# NUC200AE_v1 register map
File version: 1.0
Registers are 32-bit, read-write, reset 0x0 unless marked. A register's access mark holds for its fields unless they carry their own. Offsets are from the block's base; [hi:lo] are bit positions; {n}, {i} and the like mark numbered series.

## PDMA_GCR — PDMA Register Map
Base 0x50008F00
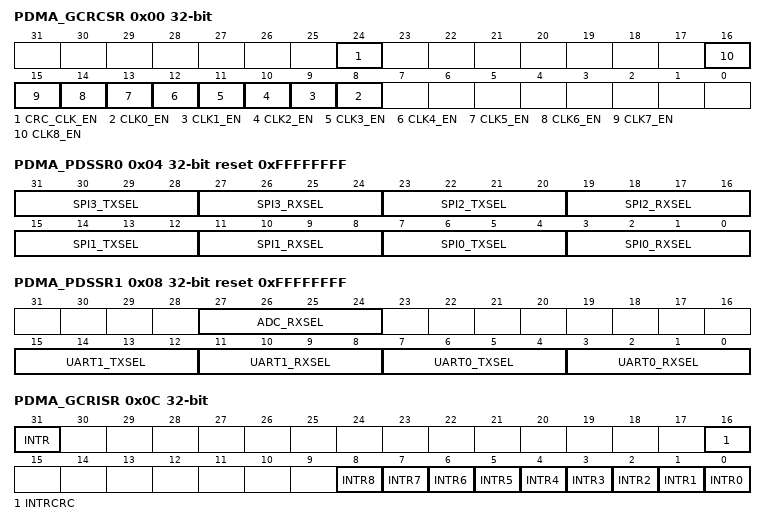
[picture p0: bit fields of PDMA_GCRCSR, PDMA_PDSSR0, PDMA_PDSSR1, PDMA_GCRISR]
0x00 PDMA_GCRCSR — PDMA Global Control Register
  [all] fields
    0=Disabled; 1=Enabled
  [24] CRC_CLK_EN — CRC Controller Clock Enable Bit
  [n+8] CLK{n}_EN (n=0..8) — PDMA Controller Channel {n} Clock Enable Bit
0x04 PDMA_PDSSR0 reset 0xFFFFFFFF — PDMA Service Selection Control Register 0
  [8n+7:8n+4] SPI{n}_TXSEL (n=0..3) — PDMA SPI{n} TX Selection. This field defines which PDMA channel is connected to the on-chip peripheral SPI{n} TX. Software can configure the TX channel setting by this field. The channel configuration is the same as SPI0_RXSEL (PDMA_PDSSR0[3:0]) field. Please refer to the explanation of SPI0_RXSEL (PDMA_PDSSR0[3:0]).
  [27:24] SPI3_RXSEL — PDMA SPI3 RX Selection. This field defines which PDMA channel is connected to the on-chip peripheral SPI3 RX. Software can configure the RX channel setting by this field. The channel configuration is the same as SPI0_RXSEL (PDMA_PDSSR0[3:0]) field. Please refer to the explanation of SPI0_RXSEL (PDMA_PDSSR0[3:0]).
  [19:16] SPI2_RXSEL — PDMA SPI2 RX Selection. This field defines which PDMA channel is connected to the on-chip peripheral SPI2 RX. Software can configure the RX channel setting by this field. The channel configuration is the same as SPI0_RXSEL (PDMA_PDSSR0[3:0]) field. Please refer to the explanation of SPI0_RXSEL (PDMA_PDSSR0[3:0]).
  [11:8] SPI1_RXSEL — PDMA SPI1 RX Selection. This field defines which PDMA channel is connected to the on-chip peripheral SPI1 RX. Software can configure the RX channel setting by this field. The channel configuration is the same as SPI0_RXSEL (PDMA_PDSSR0[3:0]) field. Please refer to the explanation of SPI0_RXSEL (PDMA_PDSSR0[3:0]).
  [3:0] SPI0_RXSEL — PDMA SPI0 RX Selection. 0000: CH0. 0001: CH1. 0010: CH2. 0011: CH3. 0100: CH4. 0101: CH5. 0110: CH6. 0111: CH7. 1000: CH8. Others : Reserved
0x08 PDMA_PDSSR1 reset 0xFFFFFFFF — PDMA Service Selection Control Register 1
  [27:24] ADC_RXSEL — PDMA ADC RX Selection. This field defines which PDMA channel is connected to the on-chip peripheral ADC RX. Software can configure the RX channel setting by this field. The channel configuration is the same as UART0_RXSEL (PDMA_PDSSR1[3:0]) field. Please refer to the explanation of UART0_RXSEL (PDMA_PDSSR1[3:0]).
  [15:12] UART1_TXSEL — PDMA UART1 TX Selection. This field defines which PDMA channel is connected to the on-chip peripheral UART1 TX. Software can configure the TX channel setting by this field. The channel configuration is the same as UART0_RXSEL (PDMA_PDSSR1[3:0]) field. Please refer to the explanation of UART0_RXSEL (PDMA_PDSSR1[3:0]).
  [11:8] UART1_RXSEL — PDMA UART1 RX Selection. This field defines which PDMA channel is connected to the on-chip peripheral UART1 RX. Software can configure the RX channel setting by this field. The channel configuration is the same as UART0_RXSEL (PDMA_PDSSR1[3:0]) field. Please refer to the explanation of UART0_RXSEL (PDMA_PDSSR1[3:0]).
  [7:4] UART0_TXSEL — PDMA UART0 TX Selection. This field defines which PDMA channel is connected to the on-chip peripheral UART0 TX. Software can configure the TX channel setting by this field. The channel configuration is the same as UART0_RXSEL (PDMA_PDSSR1[3:0]) field. Please refer to the explanation of UART0_RXSEL (PDMA_PDSSR1[3:0]).
  [3:0] UART0_RXSEL — PDMA UART0 RX Selection. 0000: CH0. 0001: CH1. 0010: CH2. 0011: CH3. 0100: CH4. 0101: CH5. 0110: CH6. 0111: CH7. 1000: CH8. Others : Reserved
0x0C PDMA_GCRISR ro — PDMA Global Interrupt Status Register
  [31] INTR — Interrupt Status. This bit is the interrupt status of PDMA controller. Note: This bit is read only.
  [16] INTRCRC — Interrupt Status Of CRC Controller. This bit is the interrupt status of CRC controller. Note: This bit is read only
  [n] INTR{n} (n=0..8) — Interrupt Status Of Channel {n}. This bit is the interrupt status of PDMA channel{n}. Note: This bit is read only.
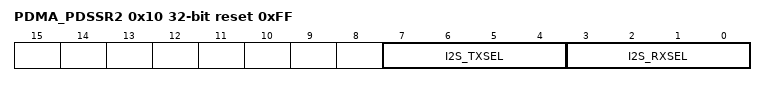
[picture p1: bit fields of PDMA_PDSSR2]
0x10 PDMA_PDSSR2 reset 0xFF — PDMA Service Selection Control Register 2
  [7:4] I2S_TXSEL — PDMA I2S TX Selection. This field defines which PDMA channel is connected to the on-chip peripheral I2S TX. Software can configure the TX channel setting by this field. The channel configuration is the same as I2S_RXSEL (PDMA_PDSSR2[3:0]) field. Please refer to the explanation of I2S_RXSEL (PDMA_PDSSR2[3:0]).
  [3:0] I2S_RXSEL — PDMA I2S RX Selection. 0000: CH0. 0001: CH1. 0010: CH2. 0011: CH3. 0100: CH4. 0101: CH5. 0110: CH6. 0111: CH7. 1000: CH8. Others : Reserved
